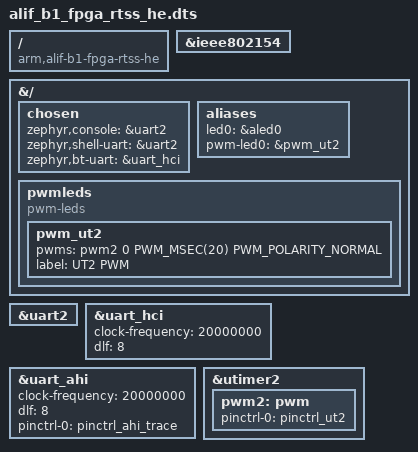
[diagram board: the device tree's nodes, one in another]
/* Copyright (c) 2024 Alif Semiconductor
 *
 * SPDX-License-Identifier: Apache-2.0
 */
/dts-v1/;

#include <alif/balletto_fpga_rtss_common.dtsi>
#include <alif/balletto-fpga-pinctrl.dtsi>

/ {
	compatible = "arm,alif-b1-fpga-rtss-he";
	#address-cells = <1>;
	#size-cells = <1>;

};
&ieee802154 {
	status = "okay";
};

&{/} {
	chosen {
		zephyr,console = &uart2;
		zephyr,shell-uart = &uart2;
		zephyr,bt-uart = &uart_hci;
	};

	aliases {
		led0 = &aled0;
		pwm-led0 = &pwm_ut2;
	};
	pwmleds {
		compatible = "pwm-leds";
		pwm_ut2: pwm_ut2 {
			pwms = <&pwm2 0 PWM_MSEC(20) PWM_POLARITY_NORMAL>;
			label = "UT2 PWM";
		};
	};
};

&uart2 {
	status = "okay";
};

&uart_hci {
	/* [MV] with 24M the divisor is 1.5 to get 1M.
	 * So use DLF=8 (0.5) and 20M clock to get integer divisor 1
	 */
	clock-frequency = <20000000>;
	dlf = <8>;
};

&uart_ahi {
	/* [MV] with 24M the divisor is 1.5 to get 1M.
	 * So use DLF=8 (0.5) and 20M clock to get integer divisor 1
	 */
	clock-frequency = <20000000>;
	dlf = <8>;
	pinctrl-0 = < &pinctrl_ahi_trace >;
	pinctrl-names = "default";
};

&utimer2 {
	status = "okay";

	pwm2: pwm {
		pinctrl-0 = < &pinctrl_ut2 >;
		pinctrl-names = "default";
		status = "okay";
	};
};
